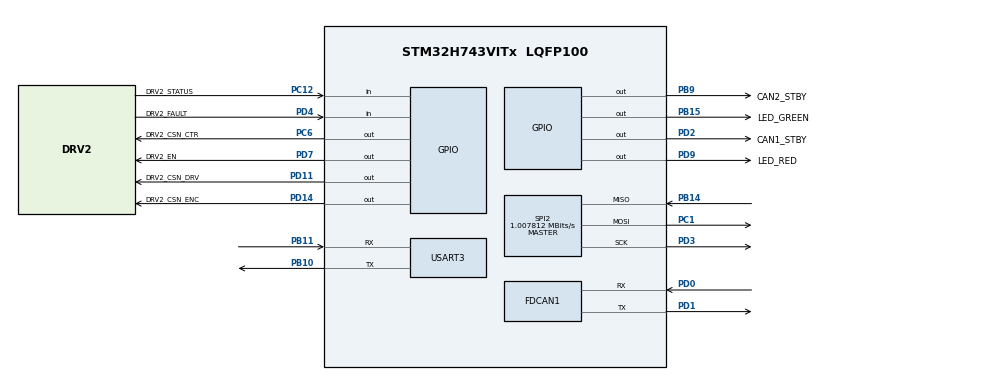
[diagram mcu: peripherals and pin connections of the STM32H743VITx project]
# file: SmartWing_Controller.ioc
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FDCAN1.DataPrescaler=4
FDCAN1.DataTimeSeg1=2
FDCAN1.DataTimeSeg2=2
FDCAN1.FrameFormat=FDCAN_FRAME_FD_BRS
FDCAN1.NominalPrescaler=2
FDCAN1.NominalTimeSeg1=23
FDCAN1.NominalTimeSeg2=16
FDCAN1.RxBufferSize=FDCAN_DATA_BYTES_64
FDCAN1.RxBuffersNbr=4
FDCAN1.RxFifo0ElmtSize=FDCAN_DATA_BYTES_64
FDCAN1.RxFifo0ElmtsNbr=4
FDCAN1.RxFifo1ElmtSize=FDCAN_DATA_BYTES_64
FDCAN1.RxFifo1ElmtsNbr=4
FDCAN1.StdFiltersNbr=2
FDCAN1.TxBuffersNbr=4
FDCAN1.TxElmtSize=FDCAN_DATA_BYTES_64
FDCAN1.TxFifoQueueElmtsNbr=4
Mcu.Family=STM32H7
Mcu.Name=STM32H743VITx
Mcu.Package=LQFP100
NVIC.PriorityGroup=NVIC_PRIORITYGROUP_4
NVIC.SPI2_IRQn=true\:0\:0\:false\:false\:true\:true\:true
NVIC.TIM2_IRQn=true\:0\:0\:false\:false\:true\:true\:true
NVIC.USART3_IRQn=true\:0\:0\:false\:false\:true\:true\:true
PA13\ (JTMS/SWDIO).Mode=Serial_Wire
PA13\ (JTMS/SWDIO).Signal=DEBUG_JTMS-SWDIO
PA14\ (JTCK/SWCLK).Mode=Serial_Wire
PA14\ (JTCK/SWCLK).Signal=DEBUG_JTCK-SWCLK
PB10.Mode=Asynchronous
PB10.Signal=USART3_TX
PB11.Mode=Asynchronous
PB11.Signal=USART3_RX
PB14.Mode=Full_Duplex_Master
PB14.Signal=SPI2_MISO
PB15.GPIO_Label=LED_GREEN
PB15.Signal=GPIO_Output
PB9.GPIO_Label=CAN2_STBY
PB9.PinState=GPIO_PIN_RESET
PB9.Signal=GPIO_Output
PC1.Mode=Full_Duplex_Master
PC1.Signal=SPI2_MOSI
PC12.GPIO_Label=DRV2_STATUS
PC12.GPIO_PuPd=GPIO_PULLDOWN
PC12.Signal=GPIO_Input
PC6.GPIO_Label=DRV2_CSN_CTR
PC6.PinState=GPIO_PIN_SET
PC6.Signal=GPIO_Output
PD0.Mode=FDCAN_Activate
PD0.Signal=FDCAN1_RX
PD1.Mode=FDCAN_Activate
PD1.Signal=FDCAN1_TX
PD11.GPIO_Label=DRV2_CSN_DRV
PD11.PinState=GPIO_PIN_SET
PD11.Signal=GPIO_Output
PD14.GPIO_Label=DRV2_CSN_ENC
PD14.PinState=GPIO_PIN_SET
PD14.Signal=GPIO_Output
PD2.GPIO_Label=CAN1_STBY
PD2.PinState=GPIO_PIN_RESET
PD2.Signal=GPIO_Output
PD3.Mode=Full_Duplex_Master
PD3.Signal=SPI2_SCK
PD4.GPIO_Label=DRV2_FAULT
PD4.GPIO_PuPd=GPIO_PULLDOWN
PD4.Signal=GPIO_Input
PD7.GPIO_Label=DRV2_EN
PD7.Signal=GPIO_Output
PD9.GPIO_Label=LED_RED
PD9.Signal=GPIO_Output
ProjectManager.HeapSize=0x200
ProjectManager.StackSize=0x400
ProjectManager.TargetToolchain=STM32CubeIDE
RCC.ADCCLockSelection=RCC_ADCCLKSOURCE_PLL3
RCC.ADCFreq_Value=129000000
RCC.APB1Freq_Value=64000000
RCC.APB2Freq_Value=64000000
RCC.APB3Freq_Value=64000000
RCC.APB4Freq_Value=64000000
RCC.CortexFreq_Value=64000000
RCC.DIVN2=80
RCC.FDCANCLockSelection=RCC_FDCANCLKSOURCE_PLL2
RCC.HCLKFreq_Value=64000000
RCC.PWR_Regulator_Voltage_Scale=PWR_REGULATOR_VOLTAGE_SCALE1
RCC.SYSCLKFreq_VALUE=64000000
RCC.USBCLockSelection=RCC_USBCLKSOURCE_HSI48
RCC.USBFreq_Value=48000000
SPI2.BaudRatePrescaler=SPI_BAUDRATEPRESCALER_128
SPI2.CLKPhase=SPI_PHASE_2EDGE
SPI2.CLKPolarity=SPI_POLARITY_HIGH
SPI2.CalculateBaudRate=1.007812 MBits/s
SPI2.DataSize=SPI_DATASIZE_8BIT
SPI2.Direction=SPI_DIRECTION_2LINES
SPI2.MasterKeepIOState=SPI_MASTER_KEEP_IO_STATE_ENABLE
SPI2.Mode=SPI_MODE_MASTER
SPI2.VirtualType=VM_MASTER
TIM2.Period=0xffffffff
TIM2.Prescaler=63
USART3.VirtualMode-Asynchronous=VM_ASYNC
VP_TIM2_VS_ClockSourceINT.Mode=Internal
board=custom

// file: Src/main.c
/* USER CODE BEGIN Header */
/**
  ******************************************************************************
  * @file           : main.c
  * @brief          : Main program body
  ******************************************************************************
  * @attention
  *
  * <h2><center>&copy; Copyright (c) 2019 STMicroelectronics.
  * All rights reserved.</center></h2>
  *
  * This software component is licensed by ST under BSD 3-Clause license,
  * the "License"; You may not use this file except in compliance with the
  * License. You may obtain a copy of the License at:
  *                        opensource.org/licenses/BSD-3-Clause
  *
  ******************************************************************************
  */
/* USER CODE END Header */
#include "main.h"
#include "fdcan.h"
#include "spi.h"
#include "tim.h"
#include "usart.h"
#include "gpio.h"

/* USER CODE BEGIN Includes */
#include <stdio.h>
#include "logic.h"
/* USER CODE END Includes */

/* USER CODE BEGIN PV */
/* Private variables ---------------------------------------------------------*/

/* USER CODE END PV */

void SystemClock_Config(void);
/* USER CODE BEGIN PFP */
/* Private function prototypes -----------------------------------------------*/

/* USER CODE END PFP */

int main(void)
{

  /* MCU Configuration--------------------------------------------------------*/

  /* Reset of all peripherals, Initializes the Flash interface and the Systick. */
  HAL_Init();

  /* Configure the system clock */
  SystemClock_Config();

  /* Initialize all configured peripherals */
  MX_GPIO_Init();
  MX_SPI2_Init();
  MX_USART3_UART_Init();
  MX_TIM2_Init();
  MX_FDCAN1_Init();
  /* USER CODE BEGIN 2 */

  logic_init();

  /* USER CODE END 2 */

  /* Infinite loop */
  /* USER CODE BEGIN WHILE */
  while (1)
  {
	  logic_loop();

    /* USER CODE END WHILE */

  }
}

void SystemClock_Config(void)
{
  RCC_OscInitTypeDef RCC_OscInitStruct = {0};
  RCC_ClkInitTypeDef RCC_ClkInitStruct = {0};

  /** Supply configuration update enable
  */
  HAL_PWREx_ConfigSupply(PWR_LDO_SUPPLY);
  /** Configure the main internal regulator output voltage
  */
  __HAL_PWR_VOLTAGESCALING_CONFIG(PWR_REGULATOR_VOLTAGE_SCALE1);

  while(!__HAL_PWR_GET_FLAG(PWR_FLAG_VOSRDY)) {}
  /** Macro to configure the PLL clock source
  */
  __HAL_RCC_PLL_PLLSOURCE_CONFIG(RCC_PLLSOURCE_HSI);
  /** Initializes the RCC Oscillators according to the specified parameters
  * in the RCC_OscInitTypeDef structure.
  */
  RCC_OscInitStruct.OscillatorType = RCC_OSCILLATORTYPE_HSI;
  RCC_OscInitStruct.HSIState = RCC_HSI_DIV1;
  RCC_OscInitStruct.HSICalibrationValue = RCC_HSICALIBRATION_DEFAULT;
  RCC_OscInitStruct.PLL.PLLState = RCC_PLL_ON;
  RCC_OscInitStruct.PLL.PLLSource = RCC_PLLSOURCE_HSI;
  RCC_OscInitStruct.PLL.PLLM = 32;
  RCC_OscInitStruct.PLL.PLLN = 129;
  RCC_OscInitStruct.PLL.PLLP = 2;
  RCC_OscInitStruct.PLL.PLLQ = 2;
  RCC_OscInitStruct.PLL.PLLR = 2;
  RCC_OscInitStruct.PLL.PLLRGE = RCC_PLL1VCIRANGE_1;
  RCC_OscInitStruct.PLL.PLLVCOSEL = RCC_PLL1VCOWIDE;
  RCC_OscInitStruct.PLL.PLLFRACN = 0;
  if (HAL_RCC_OscConfig(&RCC_OscInitStruct) != HAL_OK)
  {
    Error_Handler();
  }
  /** Initializes the CPU, AHB and APB buses clocks
  */
  RCC_ClkInitStruct.ClockType = RCC_CLOCKTYPE_HCLK|RCC_CLOCKTYPE_SYSCLK
                              |RCC_CLOCKTYPE_PCLK1|RCC_CLOCKTYPE_PCLK2
                              |RCC_CLOCKTYPE_D3PCLK1|RCC_CLOCKTYPE_D1PCLK1;
  RCC_ClkInitStruct.SYSCLKSource = RCC_SYSCLKSOURCE_HSI;
  RCC_ClkInitStruct.SYSCLKDivider = RCC_SYSCLK_DIV1;
  RCC_ClkInitStruct.AHBCLKDivider = RCC_HCLK_DIV1;
  RCC_ClkInitStruct.APB3CLKDivider = RCC_APB3_DIV1;
  RCC_ClkInitStruct.APB1CLKDivider = RCC_APB1_DIV1;
  RCC_ClkInitStruct.APB2CLKDivider = RCC_APB2_DIV1;
  RCC_ClkInitStruct.APB4CLKDivider = RCC_APB4_DIV1;

  if (HAL_RCC_ClockConfig(&RCC_ClkInitStruct, FLASH_LATENCY_0) != HAL_OK)
  {
    Error_Handler();
  }
}

void Error_Handler(void)
{
  /* USER CODE BEGIN Error_Handler_Debug */
  /* User can add his own implementation to report the HAL error return state */
	char string[64];
	uint16_t len = snprintf(string, 64, "\n\n\nHAL error\n");
	HAL_UART_Transmit(&huart3, (uint8_t*)string, len, 100000000);
  while(1)
  {
  }
  /* USER CODE END Error_Handler_Debug */
}
